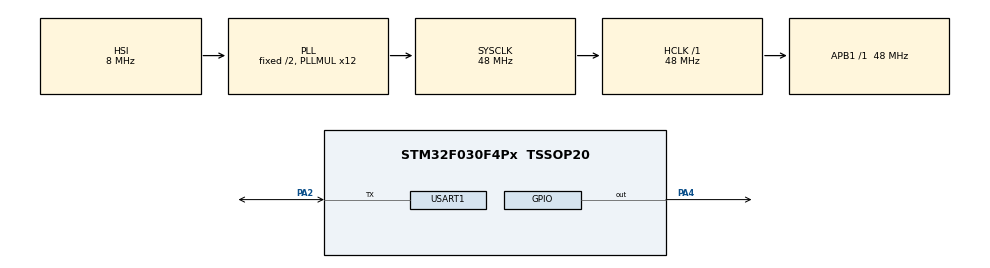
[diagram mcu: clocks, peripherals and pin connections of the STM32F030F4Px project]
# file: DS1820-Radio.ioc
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Mcu.Family=STM32F0
Mcu.Name=STM32F030F4Px
Mcu.Package=TSSOP20
NVIC.TIM1_BRK_UP_TRG_COM_IRQn=true\:0\:0\:false\:false\:true\:true\:true
PA13.Mode=Serial_Wire
PA13.Signal=SYS_SWDIO
PA14.Mode=Serial_Wire
PA14.Signal=SYS_SWCLK
PA2.Mode=Half_duplex(single_wire_mode)
PA2.Signal=USART1_TX
PA4.Signal=GPIO_Output
ProjectManager.HeapSize=0x200
ProjectManager.StackSize=0x400
ProjectManager.TargetToolchain=STM32CubeIDE
RCC.AHBFreq_Value=48000000
RCC.APB1Freq_Value=48000000
RCC.APB1TimFreq_Value=48000000
RCC.HCLKFreq_Value=48000000
RCC.PLLMUL=RCC_PLL_MUL12
RCC.SYSCLKFreq_VALUE=48000000
RCC.SYSCLKSource=RCC_SYSCLKSOURCE_PLLCLK
TIM1.Prescaler=5000
TIM3.Prescaler=47
USART1.BaudRate=115200
USART1.VirtualMode-Half_duplex(single_wire_mode)=VM_ASYNC
VP_TIM1_VS_ClockSourceINT.Mode=Internal
VP_TIM3_VS_ClockSourceINT.Mode=Internal
board=custom

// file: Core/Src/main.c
/* USER CODE BEGIN Header */
/**
 ******************************************************************************
 * @file           : main.c
 * @brief          : Main program body
 ******************************************************************************
 * @attention
 *
 * Copyright (c) 2022 STMicroelectronics.
 * All rights reserved.
 *
 * This software is licensed under terms that can be found in the LICENSE file
 * in the root directory of this software component.
 * If no LICENSE file comes with this software, it is provided AS-IS.
 *
 ******************************************************************************
 */
/* USER CODE END Header */
#include "main.h"

/* USER CODE BEGIN Includes */
#include "my_lib.h"
#include "433_TX.h"
#include "DS1820.h"

/* USER CODE END Includes */

TIM_HandleTypeDef htim1;
TIM_HandleTypeDef htim3;

UART_HandleTypeDef huart1;

/* USER CODE BEGIN PV */
uint16_t bf[10];
uint32_t water;
GPIO_PinState pin9 = 0;
uint16_t *idBase0 = (uint16_t*) (UID_BASE);
uint16_t *idBase1 = (uint16_t*) (UID_BASE + 0x02);
uint32_t *idBase2 = (uint32_t*) (UID_BASE + 0x04);
uint32_t *idBase3 = (uint32_t*) (UID_BASE + 0x08);
int32_t id;

/* USER CODE END PV */

void SystemClock_Config(void);
static void MX_GPIO_Init(void);
static void MX_TIM3_Init(void);
static void MX_USART1_UART_Init(void);
static void MX_TIM1_Init(void);
/* USER CODE BEGIN PFP */
int make_buff(char *buff, uint8_t operation);
uint8_t counter = 0;
int t;
unsigned long int tmp = 0;
long int temperature = 0;
uint16_t i;
/* USER CODE END PFP */

int main(void) {
	/* USER CODE BEGIN 1 */
	id = *idBase0 + *idBase1 + *idBase2 + *idBase3;
	/* USER CODE END 1 */

	/* MCU Configuration--------------------------------------------------------*/

	/* Reset of all peripherals, Initializes the Flash interface and the Systick. */
	HAL_Init();

	/* Configure the system clock */
	SystemClock_Config();

	/* Initialize all configured peripherals */
	MX_GPIO_Init();
	MX_TIM3_Init();
	MX_USART1_UART_Init();
	MX_TIM1_Init();
	/* USER CODE BEGIN 2 */
	//HAL_Delay(600);
    tmp = id & 0xff;
	HAL_Delay(id & 0xff); // задаем индивидуальную задержку после включения, что-бы после включения питания во всем доме датчики передавали данные не одновременно
	char *buff;

	/* USER CODE END 2 */

	/* Infinite loop */
	while (1) {

		/* USER CODE BEGIN 3 */

		temperature = 0;
		counter = 0;

		for (i = 0; i < 20; i++) {
			MX_USART1_UART_Init();
			HAL_Delay(700+(id & 0xff));
			t = DS1820_GetTemp();
			if (t != -2000) {
				counter++;
				temperature += t;
			}

		}
        tmp = HAL_GetTick() - tmp;
		if (counter) {
			temperature /= counter;
			buff = d433_buff;
			HAL_TIM_Base_Start(&htim3);
			buff = buff_copy(buff, "ID;", 3);
			buff = long_to_buff(buff, id);
			buff = buff_copy(buff, ";T;", 3);
			buff = long_to_buff(buff, temperature);
			D433_sendData(d433_buff, buff - d433_buff);
			HAL_TIM_Base_Stop(&htim3);
		}

		/*
		HAL_SuspendTick();
		HAL_TIM_Base_Start_IT(&htim1);
		HAL_PWR_EnterSLEEPMode(PWR_LOWPOWERREGULATOR_ON, PWR_SLEEPENTRY_WFI);
		HAL_ResumeTick();
		HAL_TIM_Base_Stop_IT(&htim1);
		HAL_NVIC_SystemReset();
        */
	}
	/* USER CODE END 3 */
}

void SystemClock_Config(void) {
	RCC_OscInitTypeDef RCC_OscInitStruct = { 0 };
	RCC_ClkInitTypeDef RCC_ClkInitStruct = { 0 };
	RCC_PeriphCLKInitTypeDef PeriphClkInit = { 0 };

	/** Initializes the RCC Oscillators according to the specified parameters
	 * in the RCC_OscInitTypeDef structure.
	 */
	RCC_OscInitStruct.OscillatorType = RCC_OSCILLATORTYPE_HSI;
	RCC_OscInitStruct.HSIState = RCC_HSI_ON;
	RCC_OscInitStruct.HSICalibrationValue = RCC_HSICALIBRATION_DEFAULT;
	RCC_OscInitStruct.PLL.PLLState = RCC_PLL_ON;
	RCC_OscInitStruct.PLL.PLLSource = RCC_PLLSOURCE_HSI;
	RCC_OscInitStruct.PLL.PLLMUL = RCC_PLL_MUL12;
	RCC_OscInitStruct.PLL.PREDIV = RCC_PREDIV_DIV1;
	if (HAL_RCC_OscConfig(&RCC_OscInitStruct) != HAL_OK) {
		Error_Handler();
	}
	/** Initializes the CPU, AHB and APB buses clocks
	 */
	RCC_ClkInitStruct.ClockType = RCC_CLOCKTYPE_HCLK | RCC_CLOCKTYPE_SYSCLK
			| RCC_CLOCKTYPE_PCLK1;
	RCC_ClkInitStruct.SYSCLKSource = RCC_SYSCLKSOURCE_PLLCLK;
	RCC_ClkInitStruct.AHBCLKDivider = RCC_SYSCLK_DIV1;
	RCC_ClkInitStruct.APB1CLKDivider = RCC_HCLK_DIV1;

	if (HAL_RCC_ClockConfig(&RCC_ClkInitStruct, FLASH_LATENCY_1) != HAL_OK) {
		Error_Handler();
	}
	PeriphClkInit.PeriphClockSelection = RCC_PERIPHCLK_USART1;
	PeriphClkInit.Usart1ClockSelection = RCC_USART1CLKSOURCE_PCLK1;
	if (HAL_RCCEx_PeriphCLKConfig(&PeriphClkInit) != HAL_OK) {
		Error_Handler();
	}
}

static void MX_TIM1_Init(void) {

	TIM_ClockConfigTypeDef sClockSourceConfig = { 0 };
	TIM_MasterConfigTypeDef sMasterConfig = { 0 };

	htim1.Instance = TIM1;
	htim1.Init.Prescaler = 5000;
	htim1.Init.CounterMode = TIM_COUNTERMODE_UP;
	htim1.Init.Period = 65535;
	htim1.Init.ClockDivision = TIM_CLOCKDIVISION_DIV1;
	htim1.Init.RepetitionCounter = 0;
	htim1.Init.AutoReloadPreload = TIM_AUTORELOAD_PRELOAD_DISABLE;
	if (HAL_TIM_Base_Init(&htim1) != HAL_OK) {
		Error_Handler();
	}
	sClockSourceConfig.ClockSource = TIM_CLOCKSOURCE_INTERNAL;
	if (HAL_TIM_ConfigClockSource(&htim1, &sClockSourceConfig) != HAL_OK) {
		Error_Handler();
	}
	sMasterConfig.MasterOutputTrigger = TIM_TRGO_RESET;
	sMasterConfig.MasterSlaveMode = TIM_MASTERSLAVEMODE_DISABLE;
	if (HAL_TIMEx_MasterConfigSynchronization(&htim1, &sMasterConfig)
			!= HAL_OK) {
		Error_Handler();
	}

}

static void MX_TIM3_Init(void) {

	TIM_ClockConfigTypeDef sClockSourceConfig = { 0 };
	TIM_MasterConfigTypeDef sMasterConfig = { 0 };

	htim3.Instance = TIM3;
	htim3.Init.Prescaler = 47;
	htim3.Init.CounterMode = TIM_COUNTERMODE_UP;
	htim3.Init.Period = 65535;
	htim3.Init.ClockDivision = TIM_CLOCKDIVISION_DIV1;
	htim3.Init.AutoReloadPreload = TIM_AUTORELOAD_PRELOAD_DISABLE;
	if (HAL_TIM_Base_Init(&htim3) != HAL_OK) {
		Error_Handler();
	}
	sClockSourceConfig.ClockSource = TIM_CLOCKSOURCE_INTERNAL;
	if (HAL_TIM_ConfigClockSource(&htim3, &sClockSourceConfig) != HAL_OK) {
		Error_Handler();
	}
	sMasterConfig.MasterOutputTrigger = TIM_TRGO_RESET;
	sMasterConfig.MasterSlaveMode = TIM_MASTERSLAVEMODE_DISABLE;
	if (HAL_TIMEx_MasterConfigSynchronization(&htim3, &sMasterConfig)
			!= HAL_OK) {
		Error_Handler();
	}

}

static void MX_USART1_UART_Init(void) {

	huart1.Instance = USART1;
	huart1.Init.BaudRate = 115200;
	huart1.Init.WordLength = UART_WORDLENGTH_8B;
	huart1.Init.StopBits = UART_STOPBITS_1;
	huart1.Init.Parity = UART_PARITY_NONE;
	huart1.Init.Mode = UART_MODE_TX_RX;
	huart1.Init.HwFlowCtl = UART_HWCONTROL_NONE;
	huart1.Init.OverSampling = UART_OVERSAMPLING_16;
	huart1.Init.OneBitSampling = UART_ONE_BIT_SAMPLE_DISABLE;
	huart1.AdvancedInit.AdvFeatureInit = UART_ADVFEATURE_NO_INIT;
	if (HAL_HalfDuplex_Init(&huart1) != HAL_OK) {
		Error_Handler();
	}

}

static void MX_GPIO_Init(void) {
	GPIO_InitTypeDef GPIO_InitStruct = { 0 };

	/* GPIO Ports Clock Enable */
	__HAL_RCC_GPIOF_CLK_ENABLE();
	__HAL_RCC_GPIOA_CLK_ENABLE();
	__HAL_RCC_GPIOB_CLK_ENABLE();

	/*Configure GPIO pin Output Level */
	HAL_GPIO_WritePin(GPIOA, GPIO_PIN_4, GPIO_PIN_RESET);

	/*Configure GPIO pins : PF0 PF1 */
	GPIO_InitStruct.Pin = GPIO_PIN_0 | GPIO_PIN_1;
	GPIO_InitStruct.Mode = GPIO_MODE_ANALOG;
	GPIO_InitStruct.Pull = GPIO_NOPULL;
	HAL_GPIO_Init(GPIOF, &GPIO_InitStruct);

	/*Configure GPIO pins : PA0 PA1 PA3 PA5
	 PA6 PA7 PA9 PA10 */
	GPIO_InitStruct.Pin = GPIO_PIN_0 | GPIO_PIN_1 | GPIO_PIN_3 | GPIO_PIN_5
			| GPIO_PIN_6 | GPIO_PIN_7 | GPIO_PIN_9 | GPIO_PIN_10;
	GPIO_InitStruct.Mode = GPIO_MODE_ANALOG;
	GPIO_InitStruct.Pull = GPIO_NOPULL;
	HAL_GPIO_Init(GPIOA, &GPIO_InitStruct);

	/*Configure GPIO pin : PA4 */
	GPIO_InitStruct.Pin = GPIO_PIN_4;
	GPIO_InitStruct.Mode = GPIO_MODE_OUTPUT_PP;
	GPIO_InitStruct.Pull = GPIO_NOPULL;
	GPIO_InitStruct.Speed = GPIO_SPEED_FREQ_LOW;
	HAL_GPIO_Init(GPIOA, &GPIO_InitStruct);

	/*Configure GPIO pin : PB1 */
	GPIO_InitStruct.Pin = GPIO_PIN_1;
	GPIO_InitStruct.Mode = GPIO_MODE_ANALOG;
	GPIO_InitStruct.Pull = GPIO_NOPULL;
	HAL_GPIO_Init(GPIOB, &GPIO_InitStruct);

}

void Error_Handler(void) {
	__disable_irq();
	while (1) {
	}
}
